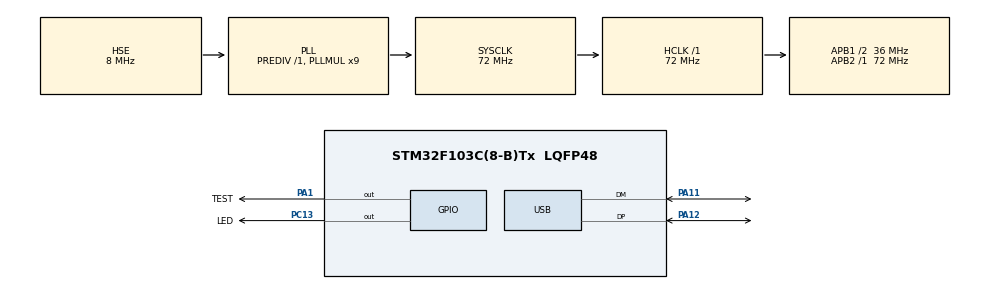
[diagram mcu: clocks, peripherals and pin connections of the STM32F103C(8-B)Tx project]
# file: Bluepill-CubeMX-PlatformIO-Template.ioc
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FREERTOS.Tasks01=blink01,8,128,StartBlink01,Default,NULL,Dynamic,NULL,NULL;blink02,9,128,StartBlink02,Default,NULL,Dynamic,NULL,NULL;USB_Serial,40,256,StartUSB_Serial,Default,NULL,Dynamic,NULL,NULL
FREERTOS.configCHECK_FOR_STACK_OVERFLOW=2
Mcu.Family=STM32F1
Mcu.Name=STM32F103C(8-B)Tx
Mcu.Package=LQFP48
NVIC.PriorityGroup=NVIC_PRIORITYGROUP_4
NVIC.RTC_IRQn=true\:5\:0\:false\:false\:true\:true\:true\:true\:true
NVIC.TIM4_IRQn=true\:15\:0\:false\:false\:true\:false\:false\:true\:true
NVIC.TimeBase=TIM4_IRQn
NVIC.TimeBaseIP=TIM4
NVIC.USB_LP_CAN1_RX0_IRQn=true\:5\:0\:false\:false\:true\:true\:false\:true\:true
PA1.GPIO_Label=TEST
PA1.GPIO_Speed=GPIO_SPEED_FREQ_HIGH
PA1.Signal=GPIO_Output
PA11.Mode=Device
PA11.Signal=USB_DM
PA12.Mode=Device
PA12.Signal=USB_DP
PA13.Mode=Serial_Wire
PA13.Signal=SYS_JTMS-SWDIO
PA14.Mode=Serial_Wire
PA14.Signal=SYS_JTCK-SWCLK
PC13-TAMPER-RTC.GPIO_Label=LED
PC13-TAMPER-RTC.GPIO_Speed=GPIO_SPEED_FREQ_HIGH
PC13-TAMPER-RTC.PinState=GPIO_PIN_SET
PC13-TAMPER-RTC.Signal=GPIO_Output
PC14-OSC32_IN.Mode=LSE-External-Oscillator
PC14-OSC32_IN.Signal=RCC_OSC32_IN
PC15-OSC32_OUT.Mode=LSE-External-Oscillator
PC15-OSC32_OUT.Signal=RCC_OSC32_OUT
PD0-OSC_IN.Mode=HSE-External-Oscillator
PD0-OSC_IN.Signal=RCC_OSC_IN
PD1-OSC_OUT.Mode=HSE-External-Oscillator
PD1-OSC_OUT.Signal=RCC_OSC_OUT
ProjectManager.HeapSize=0x200
ProjectManager.StackSize=0x400
ProjectManager.TargetToolchain=STM32CubeIDE
RCC.AHBFreq_Value=72000000
RCC.APB1CLKDivider=RCC_HCLK_DIV2
RCC.APB1Freq_Value=36000000
RCC.APB1TimFreq_Value=72000000
RCC.APB2Freq_Value=72000000
RCC.APB2TimFreq_Value=72000000
RCC.HCLKFreq_Value=72000000
RCC.PLLMUL=RCC_PLL_MUL9
RCC.PLLSourceVirtual=RCC_PLLSOURCE_HSE
RCC.RTCClockSelection=RCC_RTCCLKSOURCE_LSE
RCC.SYSCLKFreq_VALUE=72000000
RCC.SYSCLKSource=RCC_SYSCLKSOURCE_PLLCLK
RCC.USBFreq_Value=48000000
RCC.USBPrescaler=RCC_USBCLKSOURCE_PLL_DIV1_5
USB_DEVICE.CLASS_NAME_FS=CDC
USB_DEVICE.VirtualMode=Cdc
USB_DEVICE.VirtualModeFS=Cdc_FS
VP_FREERTOS_VS_CMSIS_V2.Mode=CMSIS_V2
VP_RTC_No_RTC_Output.Mode=RTC_OUT_NO
VP_RTC_VS_RTC_Activate.Mode=RTC_Enabled
VP_RTC_VS_RTC_Calendar.Mode=RTC_Calendar
VP_SYS_VS_tim4.Mode=TIM4
VP_USB_DEVICE_VS_USB_DEVICE_CDC_FS.Mode=CDC_FS
board=custom

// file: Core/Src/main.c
/* USER CODE BEGIN Header */
/**
 ******************************************************************************
 * @file           : main.c
 * @brief          : Main program body
 ******************************************************************************
 * @attention
 *
 * Copyright (c) 2022 STMicroelectronics.
 * All rights reserved.
 *
 * This software is licensed under terms that can be found in the LICENSE file
 * in the root directory of this software component.
 * If no LICENSE file comes with this software, it is provided AS-IS.
 *
 ******************************************************************************
 */
/* USER CODE END Header */
#include "main.h"
#include "cmsis_os.h"
#include "rtc.h"
#include "usb_device.h"
#include "gpio.h"

void SystemClock_Config(void);
void MX_FREERTOS_Init(void);

int main(void)
{

  /* MCU Configuration--------------------------------------------------------*/

  /* Reset of all peripherals, Initializes the Flash interface and the Systick. */
  HAL_Init();

  /* Configure the system clock */
  SystemClock_Config();

  /* Initialize all configured peripherals */
  MX_GPIO_Init();
  MX_RTC_Init();
  /* USER CODE BEGIN 2 */
  MX_USB_DEVICE_Init();
  /* USER CODE END 2 */

  /* Init scheduler */
  osKernelInitialize();  /* Call init function for freertos objects (in freertos.c) */
  MX_FREERTOS_Init();

  /* Start scheduler */
  osKernelStart();

  /* We should never get here as control is now taken by the scheduler */
  /* Infinite loop */
  while (1)
  {

  }
}

void SystemClock_Config(void)
{
  RCC_OscInitTypeDef RCC_OscInitStruct = {0};
  RCC_ClkInitTypeDef RCC_ClkInitStruct = {0};
  RCC_PeriphCLKInitTypeDef PeriphClkInit = {0};

  /** Initializes the RCC Oscillators according to the specified parameters
  * in the RCC_OscInitTypeDef structure.
  */
  RCC_OscInitStruct.OscillatorType = RCC_OSCILLATORTYPE_HSE|RCC_OSCILLATORTYPE_LSE;
  RCC_OscInitStruct.HSEState = RCC_HSE_ON;
  RCC_OscInitStruct.HSEPredivValue = RCC_HSE_PREDIV_DIV1;
  RCC_OscInitStruct.LSEState = RCC_LSE_ON;
  RCC_OscInitStruct.HSIState = RCC_HSI_ON;
  RCC_OscInitStruct.PLL.PLLState = RCC_PLL_ON;
  RCC_OscInitStruct.PLL.PLLSource = RCC_PLLSOURCE_HSE;
  RCC_OscInitStruct.PLL.PLLMUL = RCC_PLL_MUL9;
  if (HAL_RCC_OscConfig(&RCC_OscInitStruct) != HAL_OK)
  {
    Error_Handler();
  }

  /** Initializes the CPU, AHB and APB buses clocks
  */
  RCC_ClkInitStruct.ClockType = RCC_CLOCKTYPE_HCLK|RCC_CLOCKTYPE_SYSCLK
                              |RCC_CLOCKTYPE_PCLK1|RCC_CLOCKTYPE_PCLK2;
  RCC_ClkInitStruct.SYSCLKSource = RCC_SYSCLKSOURCE_PLLCLK;
  RCC_ClkInitStruct.AHBCLKDivider = RCC_SYSCLK_DIV1;
  RCC_ClkInitStruct.APB1CLKDivider = RCC_HCLK_DIV2;
  RCC_ClkInitStruct.APB2CLKDivider = RCC_HCLK_DIV1;

  if (HAL_RCC_ClockConfig(&RCC_ClkInitStruct, FLASH_LATENCY_2) != HAL_OK)
  {
    Error_Handler();
  }
  PeriphClkInit.PeriphClockSelection = RCC_PERIPHCLK_RTC|RCC_PERIPHCLK_USB;
  PeriphClkInit.RTCClockSelection = RCC_RTCCLKSOURCE_LSE;
  PeriphClkInit.UsbClockSelection = RCC_USBCLKSOURCE_PLL_DIV1_5;
  if (HAL_RCCEx_PeriphCLKConfig(&PeriphClkInit) != HAL_OK)
  {
    Error_Handler();
  }
}

void HAL_TIM_PeriodElapsedCallback(TIM_HandleTypeDef *htim)
{
  if (htim->Instance == TIM4) {
    HAL_IncTick();
  }
}

void Error_Handler(void)
{
  __disable_irq();
  while (1)
  {
  }
}

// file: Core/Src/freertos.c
/* USER CODE BEGIN Header */
/**
 ******************************************************************************
 * File Name          : freertos.c
 * Description        : Code for freertos applications
 ******************************************************************************
 * @attention
 *
 * Copyright (c) 2022 STMicroelectronics.
 * All rights reserved.
 *
 * This software is licensed under terms that can be found in the LICENSE file
 * in the root directory of this software component.
 * If no LICENSE file comes with this software, it is provided AS-IS.
 *
 ******************************************************************************
 */
/* USER CODE END Header */

#include "FreeRTOS.h"
#include "task.h"
#include "main.h"
#include "cmsis_os.h"

/* USER CODE BEGIN Includes */
#include "usb_serial.h"
#include "usbd_cdc_if.h"
#include "rtc.h"
/* USER CODE END Includes */

/* USER CODE BEGIN Variables */
int counter01, counter02, counter03, counter04 = 0;

/* USER CODE END Variables */
/* Definitions for blink01 */
osThreadId_t blink01Handle;
const osThreadAttr_t blink01_attributes = {
  .name = "blink01",
  .stack_size = 128 * 4,
  .priority = (osPriority_t) osPriorityLow,
};
/* Definitions for blink02 */
osThreadId_t blink02Handle;
const osThreadAttr_t blink02_attributes = {
  .name = "blink02",
  .stack_size = 128 * 4,
  .priority = (osPriority_t) osPriorityLow1,
};
/* Definitions for USB_Serial */
osThreadId_t USB_SerialHandle;
const osThreadAttr_t USB_Serial_attributes = {
  .name = "USB_Serial",
  .stack_size = 256 * 4,
  .priority = (osPriority_t) osPriorityHigh,
};

void StartBlink01(void *argument);
void StartBlink02(void *argument);
void StartUSB_Serial(void *argument);

extern void MX_USB_DEVICE_Init(void);
void MX_FREERTOS_Init(void); /* (MISRA C 2004 rule 8.1) */

/* Hook prototypes */
void vApplicationStackOverflowHook(xTaskHandle xTask, signed char *pcTaskName);

/* USER CODE BEGIN 4 */
void vApplicationStackOverflowHook(xTaskHandle xTask, signed char *pcTaskName)
{
   /* Run time stack overflow checking is performed if
   configCHECK_FOR_STACK_OVERFLOW is defined to 1 or 2. This hook function is
   called if a stack overflow is detected. */
   CDC_Transmit_FS("overflow", strlen("overflow"));
}
/* USER CODE END 4 */

void MX_FREERTOS_Init(void) {

  /* Create the thread(s) */
  /* creation of blink01 */
  blink01Handle = osThreadNew(StartBlink01, NULL, &blink01_attributes);

  /* creation of blink02 */
  blink02Handle = osThreadNew(StartBlink02, NULL, &blink02_attributes);

  /* creation of USB_Serial */
  USB_SerialHandle = osThreadNew(StartUSB_Serial, NULL, &USB_Serial_attributes);

}

void StartBlink01(void *argument)
{
  /* init code for USB_DEVICE */
  MX_USB_DEVICE_Init();
  /* USER CODE BEGIN StartBlink01 */
  /* Infinite loop */
  for (;;)
  {
    HAL_GPIO_TogglePin(LED_GPIO_Port, LED_Pin);
    osDelay(100);
  }
  /* USER CODE END StartBlink01 */
}

void StartBlink02(void *argument)
{
  /* USER CODE BEGIN StartBlink02 */
  /* Infinite loop */
  for (;;)
  {
    HAL_GPIO_TogglePin(LED_GPIO_Port, LED_Pin);
    osDelay(110);
  }
  /* USER CODE END StartBlink02 */
}

void StartUSB_Serial(void *argument)
{
  /* USER CODE BEGIN StartUSB_Serial */
  /* Infinite loop */
  for (;;)
  {
    usb_serial_update();
    osDelay(10);
  }
  /* USER CODE END StartUSB_Serial */
}
